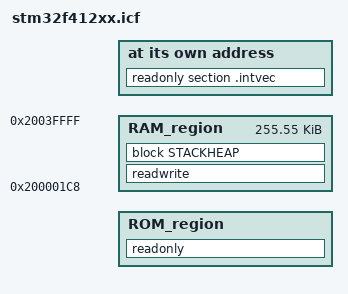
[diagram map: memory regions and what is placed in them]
if (!isdefinedsymbol(MBED_APP_START)) { define symbol MBED_APP_START = 0x08000000; }
if (!isdefinedsymbol(MBED_APP_SIZE)) { define symbol MBED_APP_SIZE = 0x100000; }

/* [ROM = 1024kb = 0x100000] */
define symbol __intvec_start__     = MBED_APP_START;
define symbol __region_ROM_start__ = MBED_APP_START;
define symbol __region_ROM_end__   = MBED_APP_START + MBED_APP_SIZE;

/* [RAM = 256kb = 0x40000] Vector table dynamic copy: 113 vectors = 452 bytes (0x1C4) to be reserved in RAM */
define symbol __NVIC_start__          = 0x20000000;
define symbol __NVIC_end__            = 0x200001C7; /* Aligned on 8 bytes */
define symbol __region_RAM_start__    = 0x200001C8;
define symbol __region_RAM_end__      = 0x2003FFFF;

/* Memory regions */
define memory mem with size = 4G;
define region ROM_region = mem:[from __region_ROM_start__ to __region_ROM_end__];
define region RAM_region = mem:[from __region_RAM_start__ to __region_RAM_end__];

/* Stack and Heap */
if (!isdefinedsymbol(MBED_BOOT_STACK_SIZE)) {
    define symbol MBED_BOOT_STACK_SIZE = 0x400;
}
define symbol __size_cstack__ = MBED_BOOT_STACK_SIZE;
define symbol __size_heap__   = 0x15000;
define block CSTACK    with alignment = 8, size = __size_cstack__   { };
define block HEAP      with alignment = 8, size = __size_heap__     { };
define block STACKHEAP with fixed order { block HEAP, block CSTACK };

initialize by copy with packing = zeros { readwrite };
do not initialize  { section .noinit };

place at address mem:__intvec_start__ { readonly section .intvec };

place in ROM_region   { readonly };
place in RAM_region   { readwrite, block STACKHEAP };
